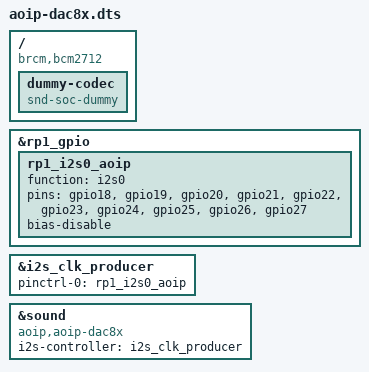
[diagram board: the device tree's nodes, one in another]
/dts-v1/;
/plugin/;

/*
 * AoIP DAC8x + ADC8x Device Tree Overlay — I2S Master Mode
 * compatible: aoip,aoip-dac8x
 * RPi(CM5)가 I2S clock producer(master) → RPi가 BCK/LRCLK 생성
 * i2s_clk_producer = RP1 i2s@a0000 (I2S0 하드웨어 블록)
 */

/ {
	compatible = "brcm,bcm2712";

	fragment@0 {
		target = <&rp1_gpio>;
		__overlay__ {
			rp1_i2s0_aoip: rp1_i2s0_aoip {
				function = "i2s0";
				pins = "gpio18", "gpio19", "gpio20", "gpio21",
				       "gpio22", "gpio23", "gpio24", "gpio25",
				       "gpio26", "gpio27";
				bias-disable;
				status = "okay";
			};
		};
	};

	fragment@1 {
		target = <&i2s_clk_producer>;
		__overlay__ {
			pinctrl-names = "default";
			pinctrl-0 = <&rp1_i2s0_aoip>;
			status = "okay";
		};
	};

	fragment@2 {
		target-path = "/";
		__overlay__ {
			dummy-codec {
				#sound-dai-cells = <0>;
				compatible = "snd-soc-dummy";
				status = "okay";
			};
		};
	};

	fragment@3 {
		target = <&sound>;
		__overlay__ {
			compatible = "aoip,aoip-dac8x";
			i2s-controller = <&i2s_clk_producer>;
			status = "okay";
		};
	};
};
